VERSION ""

NS_ :

BS_:

BU_:

BO_ 16 AccelPedals: 8 Vector__XXX
 SG_ accel_1 : 7|32@0+ (1,0) [0|0] "" Vector__XXX
 SG_ accel_2 : 39|32@0+ (1,0) [0|0] "" Vector__XXX

BO_ 17 SteeringPot: 2 Vector__XXX
 SG_ value : 7|16@0- (1,0) [0|0] "" Vector__XXX

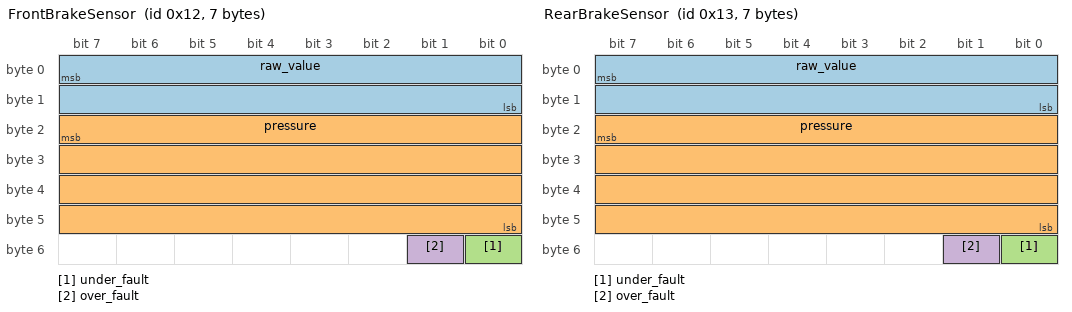
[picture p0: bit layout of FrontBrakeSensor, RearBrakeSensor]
BO_ 18 FrontBrakeSensor: 7 Vector__XXX
 SG_ raw_value : 7|16@0+ (1,0) [0|0] "" Vector__XXX
 SG_ pressure : 23|32@0+ (1,0) [0|0] "" Vector__XXX
 SG_ under_fault : 48|1@1+ (1,0) [0|0] "" Vector__XXX
 SG_ over_fault : 49|1@1+ (1,0) [0|0] "" Vector__XXX

BO_ 19 RearBrakeSensor: 7 Vector__XXX
 SG_ raw_value : 7|16@0+ (1,0) [0|0] "" Vector__XXX
 SG_ pressure : 23|32@0+ (1,0) [0|0] "" Vector__XXX
 SG_ under_fault : 48|1@1+ (1,0) [0|0] "" Vector__XXX
 SG_ over_fault : 49|1@1+ (1,0) [0|0] "" Vector__XXX

BO_ 35 ShockPotFront: 4 Vector__XXX
 SG_ proc_side : 7|16@0+ (1,0) [0|0] "" Vector__XXX
 SG_ unproc_side : 23|16@0+ (1,0) [0|0] "" Vector__XXX

BO_ 36 ShockPotRear: 4 Vector__XXX
 SG_ proc_side : 7|16@0+ (1,0) [0|0] "" Vector__XXX
 SG_ unproc_side : 23|16@0+ (1,0) [0|0] "" Vector__XXX

BO_ 240 WheelSpeed_FrontLeft: 8 Vector__XXX
 SG_ filtered_speed : 7|32@0- (1,0) [0|0] "" Vector__XXX
 SG_ raw_speed : 39|32@0- (1,0) [0|0] "" Vector__XXX

BO_ 241 WheelSpeed_FrontRight: 8 Vector__XXX
 SG_ filtered_speed : 7|32@0- (1,0) [0|0] "" Vector__XXX
 SG_ raw_speed : 39|32@0- (1,0) [0|0] "" Vector__XXX

BO_ 242 WheelSpeed_BackLeft: 8 Vector__XXX
 SG_ filtered_speed : 7|32@0- (1,0) [0|0] "" Vector__XXX
 SG_ raw_speed : 39|32@0- (1,0) [0|0] "" Vector__XXX

BO_ 243 WheelSpeed_BackRight: 8 Vector__XXX
 SG_ filtered_speed : 7|32@0- (1,0) [0|0] "" Vector__XXX
 SG_ raw_speed : 39|32@0- (1,0) [0|0] "" Vector__XXX

BO_ 245 ToggleSpeed_Front: 8 Vector__XXX
 SG_ left_speed : 7|32@0+ (1,0) [0|0] "" Vector__XXX
 SG_ right_speed : 39|32@0+ (1,0) [0|0] "" Vector__XXX

BO_ 246 ToggleSpeed_Back: 8 Vector__XXX
 SG_ left_speed : 7|32@0+ (1,0) [0|0] "" Vector__XXX
 SG_ right_speed : 39|32@0+ (1,0) [0|0] "" Vector__XXX

BO_ 247 ToggleSpeed_FrontRaw: 8 Vector__XXX
 SG_ left_speed : 7|32@0+ (1,0) [0|0] "" Vector__XXX
 SG_ right_speed : 39|32@0+ (1,0) [0|0] "" Vector__XXX

BO_ 248 ToggleSpeed_BackRaw: 8 Vector__XXX
 SG_ left_speed : 7|32@0+ (1,0) [0|0] "" Vector__XXX
 SG_ right_speed : 39|32@0+ (1,0) [0|0] "" Vector__XXX

BO_ 2045 CanSpecHash: 5 Vector__XXX
 SG_ hash : 0|32@1+ (1,0) [0|0] "" Vector__XXX
 SG_ pin_select_id : 32|8@1+ (1,0) [0|0] "" Vector__XXX

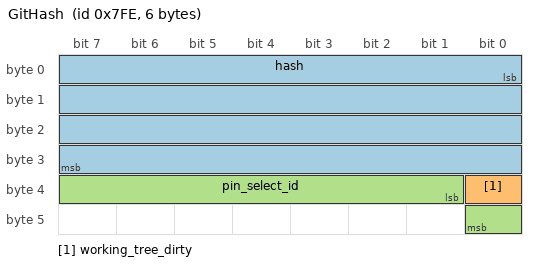
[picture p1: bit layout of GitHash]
BO_ 2046 GitHash: 6 Vector__XXX
 SG_ hash : 0|32@1+ (1,0) [0|0] "" Vector__XXX
 SG_ working_tree_dirty : 32|1@1+ (1,0) [0|0] "" Vector__XXX
 SG_ pin_select_id : 33|8@1+ (1,0) [0|0] "" Vector__XXX

BO_ 2047 SrcHash: 5 Vector__XXX
 SG_ hash : 0|32@1+ (1,0) [0|0] "" Vector__XXX
 SG_ pin_select_id : 32|8@1+ (1,0) [0|0] "" Vector__XXX

BA_DEF_  "BusType" STRING ;
BA_DEF_DEF_  "BusType" "CAN";
